# DEVICE_PRM register map
Vendor: Texas Instruments
Peripheral module from a debugger description file (folder am572x).
Registers are 32-bit, access per field, reset 0x0 unless marked. A register's access mark holds for its fields unless they carry their own. Offsets are as the file gives them; lines under a group give offsets from that group; [hi:lo] are bit positions; {n}, {i} and the like mark numbered series; 'fields as' and 'values as' point back to an identical list; <NAME> marks a mode.

## DEVICE_PRM
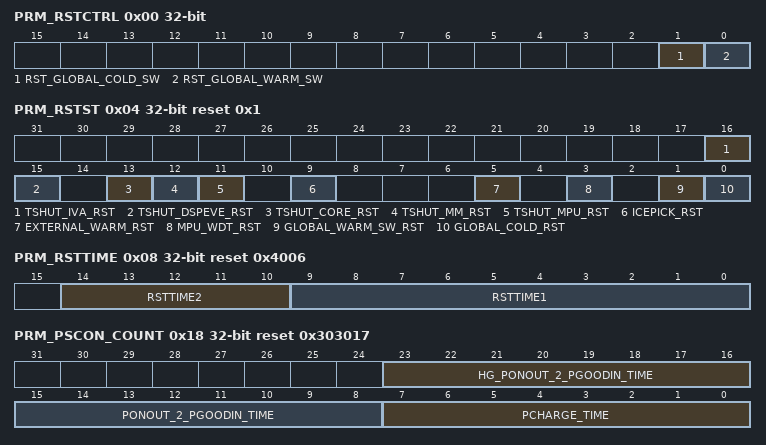
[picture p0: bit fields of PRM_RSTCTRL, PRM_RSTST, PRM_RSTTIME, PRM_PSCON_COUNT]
0x00 PRM_RSTCTRL — Global software cold and warm reset control. This register is auto-cleared. Only write 1 is possible. A read returns 0 only.
  [1] RST_GLOBAL_COLD_SW rw — Global COLD software reset control. This bit is reset only upon a global cold source of reset.
    0=Global COLD software reset is cleared; 1=Triggers a global COLD software reset. The software must ensure the SDRAM is properly put in sef-refresh mode before applying this reset.
  [0] RST_GLOBAL_WARM_SW rw — Global WARM software reset control. This bit is reset upon any global source of reset (warm and cold).
    0=Global warm software reset is cleared; 1=Triggers a global warm software reset
0x04 PRM_RSTST reset 0x1 — This register logs the global reset sources. Each bit is set upon release of the domain reset signal. Must be cleared by software. [warm reset insensitive]
  [16] TSHUT_IVA_RST rw — TSHUT_IVA warm reset event. This is a source of global WARM reset.
    0=No TSHUT_MM reset; 1=TSHUT_MM reset has occurred
  [15] TSHUT_DSPEVE_RST rw — TSHUT_DSPEVE warm reset event. This is a source of global WARM reset.
    0=No TSHUT_MM reset; 1=TSHUT_MM reset has occurred
  [13] TSHUT_CORE_RST rw — TSHUT_CORE warm reset event. This is a source of global WARM reset.
    0=No TSHUT_CORE reset; 1=TSHUT_CORE reset has occurred
  [12] TSHUT_MM_RST rw — TSHUT_GPU warm reset event. This is a source of global WARM reset.
    0=No TSHUT_MM reset; 1=TSHUT_MM reset has occurred
  [11] TSHUT_MPU_RST rw — TSHUT_MPU warm reset event. This is a source of global WARM reset.
    0=No TSHUT_MPU reset; 1=TSHUT_MPU reset has occurred
  [9] ICEPICK_RST rw — IcePick reset event. This is a source of global warm reset initiated by the emulation.
    0=No ICEPICK reset; 1=IcePick reset has occurred
  [5] EXTERNAL_WARM_RST rw — External warm reset event
    0=No global warm reset; 1=Global external warm reset has occurred
  [3] MPU_WDT_RST rw — WD_TIMER2 and MPU subsystem watchdog reset event. This is a source of global WARM reset.
    0=No reset; 1=Reset has occurred
  [1] GLOBAL_WARM_SW_RST rw — Global warm software reset event
    0=No global warm SW reset; 1=Global warm SW reset has occurred
  [0] GLOBAL_COLD_RST rw — Power-on (cold) reset event
    0=No power-on reset; 1=Power-on reset has occurred
0x08 PRM_RSTTIME reset 0x4006 — Reset duration control. [warm reset insensitive]
  [14:10] RSTTIME2 rw — Power domain reset duration 2 in number of RM.SYSCLK clock cycles.
  [9:0] RSTTIME1 rw — Global reset duration 1 in number of Func_32k_clk clock cycles. This bit-field is only sensitive to the external power-on reset (WKUPAON_SYS_PWRON_RST reset line)
0x18 PRM_PSCON_COUNT reset 0x303017 — This register allows controlling 2 parameters for power state controller. [warm reset insensitive]
  [23:16] HG_PONOUT_2_PGOODIN_TIME rw — The value 'NbCycles' set in this field determines the duration of the PONOUT to PGOODIN transition for power domain without DPS. The duration is computed as 8 x NbCycles of system clock cycles. Target is 10us.
  [15:8] PONOUT_2_PGOODIN_TIME rw — The value 'NbCycles' set in this field determines the duration of the PONOUT to PGOODIN transition for power domain without DPS. The duration is computed as 8 x NbCycles of system clock cycles. Target is 10us.
  [7:0] PCHARGE_TIME rw — Number of system clock cycles for the SRAM pre-charge duration. Target is 600ns.
0x1C PRM_IO_COUNT reset 0x3A — This register allows controlling DDR IO isolation removal setup. [warm reset insensitive]
  [7:0] ISO_2_ON_TIME rw — Determines the setup time of the DDR IOs going out of isolation. Counting on the system clock. Target is 1.5us.
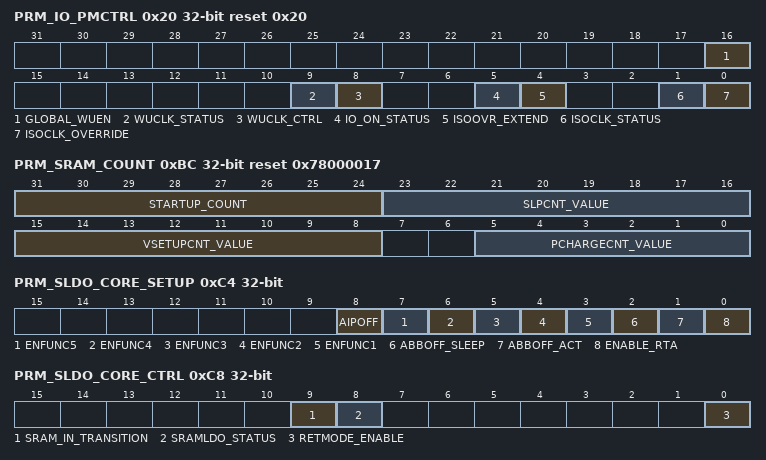
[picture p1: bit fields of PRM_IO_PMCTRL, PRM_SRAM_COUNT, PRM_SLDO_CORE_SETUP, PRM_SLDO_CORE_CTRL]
0x20 PRM_IO_PMCTRL reset 0x20 — This register allows controlling power management features of the IOs.
  [16] GLOBAL_WUEN rw — Global IO wakeup enable. This is a gating condition to all individual IO WUEN coming from control module. Gating is done in the Spinner logic.
    0=DISABLED (All individual IO WUEN are gated in the Spinner logic (overriden to 0).); 1=ENABLED (All individual IO WUEN from control module are going to IOs.)
  [9] WUCLK_STATUS ro — Gives value of WUCLKOUT signal coming back from IO pad ring.
  [8] WUCLK_CTRL rw — Direct control on WUCLKIN signal to IO pad ring.
    0=LOW (WUCLKIN signal is driven to 0. IO wakeup daisy chain is functional as well as IO whose wakeup feature is enabled.); 1=HIGH (WUCLKIN signal is driven to 1. IO wakeup daisy chain is reset and is latching current pad states and WUEN inputs.)
  [5] IO_ON_STATUS ro — Gives the functional status of the IO ring.
    0=LOW (Part or all of the IOs are not in the ON state, that is are in isolation state.); 1=HIGH (All IOs are in the ON state.)
  [4] ISOOVR_EXTEND rw — Control non-EMIF IO isolation extension upon a device wakeup from OFF mode.
    0=NOOVERRIDE (Non-EMIF IO isolation is not extended. 'EMIF_ON' IO transition happens as soon as automatic restore is completed.); 1=OVERRIDE (Non-EMIF IO isolation is extended. 'EMIF_ON' IO transition is stalled.)
  [1] ISOCLK_STATUS ro — Gives value of ISOCLKOUT signal coming back from IO pad ring.
  [0] ISOCLK_OVERRIDE rw — Override control on ISOCLKIN signal to IO pad ring. Used at boot time when it is needed to change the mode of an IO from 1.8V default mode to 1.2V mode. When not overriden, this signal is controlled by hardware only.
    0=NOOVERRIDE (ISOCLKIN signal is not overriden.); 1=OVERRIDE (ISOCLKIN signal is overriden to active value ('1').)
0xBC PRM_SRAM_COUNT reset 0x78000017 — Common setup for SRAM LDO transition counters. Applies to all voltage domains. [warm reset insensitive]
  [31:24] STARTUP_COUNT rw — Determines the start-up duration of SRAM and ABB LDO. The duration is computed as 16 x NbCycles of system clock cycles. Target is 50us.
  [23:16] SLPCNT_VALUE rw — Delay between retention/off assertion of last SRAM bank and SRAMALLRET signal to LDO is driven high. Counting on system clock. Target is 2us.
  [15:8] VSETUPCNT_VALUE rw — SRAM LDO rampup time from retention to active mode. The duration is computed as 8 x NbCycles of system clock cycles. Target is 30us.
  [5:0] PCHARGECNT_VALUE rw — Delay between de-assertion of standby_rta_ret_on and standby_rta_ret_good. Counting on system clock. Target is 600ns.
0xC4 PRM_SLDO_CORE_SETUP — Setup of the SRAM LDO for CORE voltage domain. [warm reset insensitive]
  [8] AIPOFF rw — Override on AIPOFF input of SRAM LDO.
    0=NO_OVERRIDE (AIPOFF signal is not overriden); 1=OVERRIDE (AIPOFF signal is overriden to '1'. Corresponding SRAM LDO is disabled and in HZ mode.)
  [7] ENFUNC5 rw — ENFUNC5 input of SRAM LDO.
    0=ONE_STEP (Active to retention is a one step transfer); 1=TWO_STEP (Active to retention is a two steps transfer)
  [6] ENFUNC4 rw — ENFUNC4 input of SRAM LDO.
    0=EXT_CLOCK (One external clock is supplied); 1=NO_EXT_CLOCK (No external clock is supplied)
  [5] ENFUNC3 rw — ENFUNC3 input of SRAM LDO. After PowerOn reset and Efuse sensing, this bitfield is automatically loaded with an Efuse value from control module. Bitfield remains writable after this.
    0=SUB_REGUL_DISABLED (Sub regulation is disabled); 1=SUB_REGUL_ENABLED (Sub regulation is enabled)
  [4] ENFUNC2 rw — ENFUNC2 input of SRAM LDO. After PowerOn reset and Efuse sensing, this bitfield is automatically loaded with an Efuse value from control module. Bitfield remains writable after this.
    0=EXT_CAP (External cap is used); 1=NO_EXT_CAP (External cap is not used)
  [3] ENFUNC1 rw — ENFUNC1 input of SRAM LDO. After PowerOn reset and Efuse sensing, this bitfield is automatically loaded with an Efuse value from control module. Bitfield remains writable after this.
    0=SHORT_PROT_DISABLED (Short circuit protection is disabled); 1=SHORT_PROT_ENABLED (Short circuit protection is enabled)
  [2] ABBOFF_SLEEP rw — Determines whether SRAMNWA is supplied by VDDS or VDDAR during deep-sleep. After PowerOn reset and Efuse sensing, this bitfield is automatically loaded with an Efuse value from control module. Bitfield remains writable after this.
    0=SRAMNW_SLP_VDDS (SRAMNWA supplied with VDDS); 1=SRAMNW_SLP_VDDAR (SRAMNWA supplied with VDDAR)
  [1] ABBOFF_ACT rw — Determines whether SRAMNWA is supplied by VDDS or VDDAR during active mode. After PowerOn reset and Efuse sensing, this bitfield is automatically loaded with an Efuse value from control module. Bitfield remains writable after this.
    0=SRAMNW_ACT_VDDS (SRAMNWA supplied with VDDS); 1=SRAMNW_ACT_VDDAR (SRAMNWA supplied with VDDAR)
  [0] ENABLE_RTA rw — Control for HD memory RTA feature. After PowerOn reset and Efuse sensing, this bitfield is automatically loaded with an Efuse value from control module. Bitfield remains writable after this.
    0=RTA_DISABLED (HD memory RTA feature is disabled); 1=RTA_ENABLED (HD memory RTA feature is enabled)
0xC8 PRM_SLDO_CORE_CTRL ro — Control and status of the SRAM LDO for CORE voltage domain. [warm reset insensitive]
  [9] SRAM_IN_TRANSITION — Status indicating SRAM LDO state machine state.
    0=IDLE (SRAM LDO state machine is stable); 1=IN_TRANSITION (SRAM LDO state machine is in transition state)
  [8] SRAMLDO_STATUS
    0=ACTIVE (SRAMLDO is in ACTIVE mode.); 1=RETENTION (SRAMLDO is on RETENTION mode.)
  [0] RETMODE_ENABLE — Control if the SRAM LDO retention mode is used or not.
    0=DISABLED (SRAM LDO is not allowed to go to RET mode)
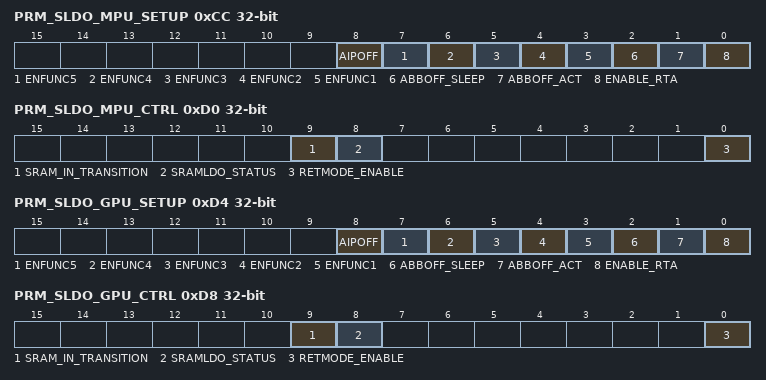
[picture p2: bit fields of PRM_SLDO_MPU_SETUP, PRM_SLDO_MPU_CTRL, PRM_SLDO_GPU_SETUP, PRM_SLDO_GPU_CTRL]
0xCC PRM_SLDO_MPU_SETUP — Setup of the SRAM LDO for MPU voltage domain. [warm reset insensitive]
  fields as PRM_SLDO_CORE_SETUP
0xD0 PRM_SLDO_MPU_CTRL — Control and status of the SRAM LDO for MPU voltage domain. [warm reset insensitive]
  [9] SRAM_IN_TRANSITION ro — Status indicating SRAM LDO state machine state.
    values as PRM_SLDO_CORE_CTRL.SRAM_IN_TRANSITION
  [8] SRAMLDO_STATUS ro
    values as PRM_SLDO_CORE_CTRL.SRAMLDO_STATUS
  [0] RETMODE_ENABLE rw — Control if the SRAM LDO retention mode is used or not.
    0=DISABLED (SRAM LDO is not allowed to go to RET mode); 1=ENABLED (SRAM LDO go to RET mode when all memory of voltage domain are OFF or RET)
0xD4 PRM_SLDO_GPU_SETUP — Setup of the SRAM LDO for GPU voltage domain. [warm reset insensitive]
  fields as PRM_SLDO_CORE_SETUP
0xD8 PRM_SLDO_GPU_CTRL — Control and status of the SRAM LDO for GPU voltage domain. [warm reset insensitive]
  fields as PRM_SLDO_MPU_CTRL
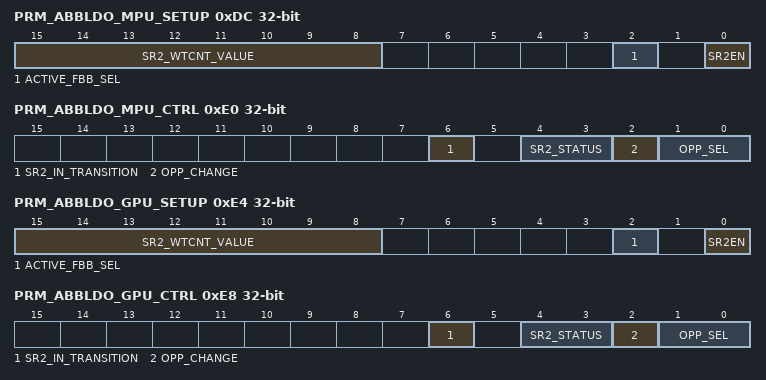
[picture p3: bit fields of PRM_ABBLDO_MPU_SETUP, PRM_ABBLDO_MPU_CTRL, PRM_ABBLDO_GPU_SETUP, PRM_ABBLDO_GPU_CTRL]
0xDC PRM_ABBLDO_MPU_SETUP — Selects the MPU_ABB LDO mode.
  [15:8] SR2_WTCNT_VALUE rw — LDO settling time for active-mode OPP change. Counting at a 16 system clock cycles rate. Target is 50us. [warm reset insensitive]
  [2] ACTIVE_FBB_SEL rw — Defines ABB LDO mode when voltage is in slow fast OPP. [warm reset insensitive]
    0=BYPASS (ABB LDO is in bypass mode); 1=FBB (ABB LDO is in FBB mode)
  [0] SR2EN rw — Enable ABB power management
    0=BYPASS (ABB LDO is put in bypass mode); 1=FUNCTIONAL (ABB LDO will operate accordingly to settings)
0xE0 PRM_ABBLDO_MPU_CTRL — Control and Status of ABB on MPU voltage domain. [warm reset insensitive]
  [6] SR2_IN_TRANSITION ro — Indicates VBBLDO_CON is or is not in transition state. This output should be used by programming interface to clear OPP_CHANGE bit as an indication of OPP change completion.
    0=IDLE; 1=INTRANSITION (Indicates that VBBLDO_CON is in transition and SR2_STATUS bits are not stable to read.)
  [4:3] SR2_STATUS ro — Indicate ABB LDO current operation status
    0=BYPASS (ABB LDO is placed in bypass mode.); 2=FBB (ABB LDO is placed in FBB active mode.)
  [2] OPP_CHANGE rw — When OPP_CHANGE is set to 1, VBBLDO_CON samples OPP_SEL ACTIVE_FBB_SEL upon detecting rising edge. VBBLDO_CON asserts signal SR2_IN_TRANSITION in response to OPP_CHANGE. OPP_CHANGE should be cleared to 0 when SR2_IN_TRANSITION from VBBLDO_CON is de-asserted.
  [1:0] OPP_SEL rw — To control the ABB LDO (FBB/RBB) at a given OPP, set to 0x1. Refer to section ABB LDO Programming sequence.
    0=DEFAULT_NOMINAL; 1=FASTOPP
0xE4 PRM_ABBLDO_GPU_SETUP — Selects the GPU_ABB LDO mode.
  fields as PRM_ABBLDO_MPU_SETUP
0xE8 PRM_ABBLDO_GPU_CTRL — Control and Status of ABB on GPU voltage domain. [warm reset insensitive]
  fields as PRM_ABBLDO_MPU_CTRL
0xEC PRM_BANDGAP_SETUP reset 0x78 — Setup of the bandgap. [warm reset insensitive]
  [7:0] STARTUP_COUNT rw — Determines the start-up duration of BANDGAP. The duration is computed as 32 x NbCycles of system clock cycles. Target is 100us.
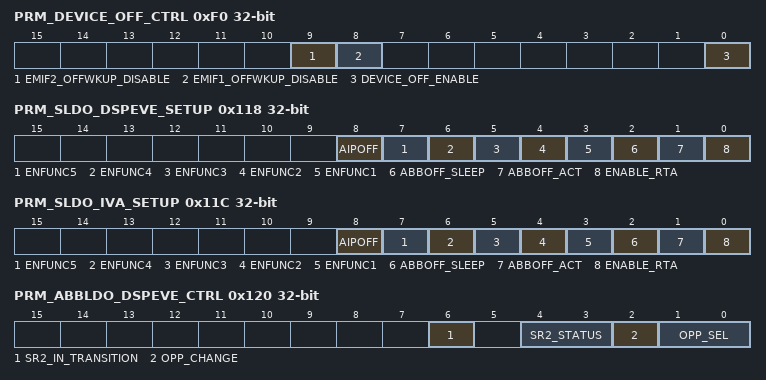
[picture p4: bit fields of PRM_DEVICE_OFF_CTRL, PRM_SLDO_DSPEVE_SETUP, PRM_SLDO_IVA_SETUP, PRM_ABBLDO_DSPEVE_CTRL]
0xF0 PRM_DEVICE_OFF_CTRL — This register is used to control device OFF transition.
  [9] EMIF2_OFFWKUP_DISABLE rw — Controls the EMIF2_DEVICE_OFFWKUP_CORESRTACTST notifier sent to EMIF1 upon a device wakeup from OFF mode. [warm reset insensitive]
    0=ENABLED (Notifier is activated.); 1=DISABLED (Notifier is not activated - stays low)
  [8] EMIF1_OFFWKUP_DISABLE rw — Controls the EMIF1_DEVICE_OFFWKUP_CORESRTACTST notifier sent to EMIF2 upon a device wakeup from OFF mode. [warm reset insensitive]
    values as EMIF2_OFFWKUP_DISABLE
  [0] DEVICE_OFF_ENABLE rw — Controls transition to device OFF mode.
    0=DISABLED (Device is not allowed to perform transition to OFF mode); 1=ENABLED (Device is allowed to perform transition to OFF mode as soon as all power domains in MPU, MM and CORE voltage are in OFF or OSWRET state (open switch retention))
0xF4 PRM_PHASE1_CNDP ro reset 0x4A05E000 — This register stores the start descriptor address of automatic restore phase1. [warm reset insensitive] NOTE: This register is NOT supported on this device.
  [31:0] PHASE1_CNDP — Start descriptor address of automatic restore phase1. Hard-coded to SAR_ROM base address.
0xF8 PRM_PHASE2A_CNDP ro reset 0x4A05E030 — This register stores the start descriptor address of automatic restore phase2A. [warm reset insensitive] NOTE: This register is NOT supported on this device.
  [31:0] PHASE2A_CNDP — Start descriptor address of automatic restore phase2A. Hard-coded to SAR_ROM base address + 0x30.
0xFC PRM_PHASE2B_CNDP ro reset 0x4A05E060 — This register stores the start descriptor address of automatic restore phase2B. [warm reset insensitive] NOTE: This register is NOT supported on this device.
  [31:0] PHASE2B_CNDP — Start descriptor address of automatic restore phase2B. Hard-coded to SAR_ROM base address + 0x60.
0x118 PRM_SLDO_DSPEVE_SETUP — Setup of the SRAM LDO for DSPEVE voltage domain. [warm reset insensitive]
  fields as PRM_SLDO_CORE_SETUP
0x11C PRM_SLDO_IVA_SETUP — Setup of the SRAM LDO for IVA voltage domain. [warm reset insensitive]
  fields as PRM_SLDO_CORE_SETUP
0x120 PRM_ABBLDO_DSPEVE_CTRL — Control and Status of ABB on DSPEVE voltage domain. [warm reset insensitive]
  fields as PRM_ABBLDO_MPU_CTRL
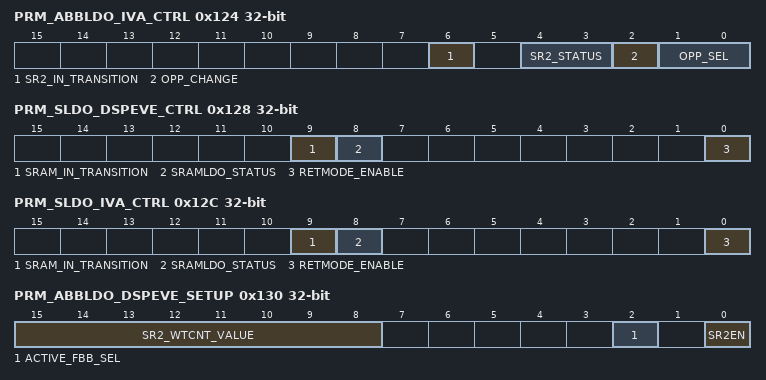
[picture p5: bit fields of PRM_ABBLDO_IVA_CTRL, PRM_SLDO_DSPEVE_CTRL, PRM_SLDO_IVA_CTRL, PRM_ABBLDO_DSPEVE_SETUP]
0x124 PRM_ABBLDO_IVA_CTRL — Control and Status of ABB on IVA voltage domain. [warm reset insensitive]
  fields as PRM_ABBLDO_MPU_CTRL
0x128 PRM_SLDO_DSPEVE_CTRL — Control and status of the SRAM LDO for CORE voltage domain. [warm reset insensitive]
  fields as PRM_SLDO_MPU_CTRL
0x12C PRM_SLDO_IVA_CTRL — Control and status of the SRAM LDO for CORE voltage domain. [warm reset insensitive]
  fields as PRM_SLDO_MPU_CTRL
0x130 PRM_ABBLDO_DSPEVE_SETUP — Selects the GPU_ABB LDO mode.
  fields as PRM_ABBLDO_MPU_SETUP
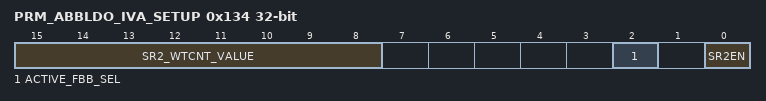
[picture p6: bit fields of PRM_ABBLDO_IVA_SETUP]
0x134 PRM_ABBLDO_IVA_SETUP — Selects the GPU_ABB LDO mode.
  fields as PRM_ABBLDO_MPU_SETUP
